# D1H register map
Vendor: Allwinner; File version: 1.0
Registers are 32-bit, read-write, reset 0x0 unless marked. A register's access mark holds for its fields unless they carry their own. Offsets are from the block's base; [hi:lo] are bit positions; {n}, {i} and the like mark numbered series; 'fields as' and 'values as' point back to an identical list.

## TWI[{n}] — Two Wire Interface
Base 0x02502000; array of 4, step 0x400
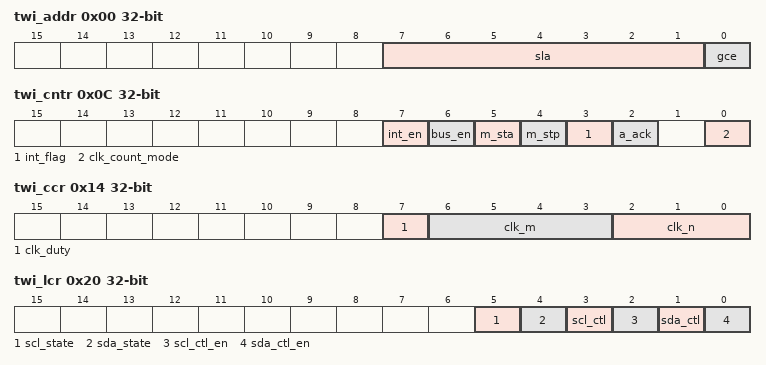
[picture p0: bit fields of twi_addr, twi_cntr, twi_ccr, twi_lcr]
0x00 twi_addr — TWI Slave Address Register
  [7:1] sla — Slave Address
  [0] gce
    0=DISABLE; 1=ENABLE
0x04 twi_xaddr — TWI Extended Slave Address Register
  [7:0] slax — Extend Slave Address . SLAX[7:0]
0x08 twi_data — TWI Data Byte Register
  [7:0] data — Data byte transmitted or received
0x0C twi_cntr — TWI Control Register
  [7] int_en — Interrupt Enable
    0=LOW (The interrupt line always low); 1=HIGH (The interrupt line will go high when INT_FLAG is set)
  [6] bus_en — TWI Bus Enable
    0=IGNORED; 1=RESPOND
  [5] m_sta — Master Mode Start
  [4] m_stp — Master Mode Stop
  [3] int_flag — Interrupt Flag
  [2] a_ack — Assert Acknowledge
  [0] clk_count_mode
    0=OSCL (scl clock high period count on oscl); 1=ISCL (scl clock high period count on iscl)
0x10 twi_stat ro — TWI Status Register
  [7:0] sta
    0=BE (Bus error); 8=SCT (START condition transmitted); 16=RSCT (Repeated START condition transmitted); 24=AWBT_AR (Address + Write bit transmitted, ACK received); 32=AWBT_ANR (Address + Write bit transmitted, ACK not received); 40=DBTM_AR (Data byte transmitted in master mode, ACK received); 48=DBTM_ANR (Data byte transmitted in master mode, ACK not received); 56=AL_A_DB (Arbitration lost in address or data byte); 64=ARBT_AR (Address + Read bit transmitted, ACK received); 72=ARBT_ANR (Address + Read bit transmitted, ACK not received); 80=DBRM_AT (Data byte received in master mode, ACK transmitted); 88=DBRM_ANT (Data byte received in master mode, not ACK transmitted); 96=SAWR_AT (Slave address + Write bit received, ACK transmitted); 104=AL_AM_SAWR_AT (Arbitration lost in the address as master, slave address + Write bit received, ACK transmitted); 112=GCAR_AT (General Call address received, ACK transmitted); 120=AL_AM_GCAR_AT (Arbitration lost in the address as master, General Call address received, ACK transmitted); 128=DBR_SAR_AT (Data byte received after slave address received, ACK transmitted); 136=DBR_SAR_ANT (Data byte received after slave address received, not ACK transmitted); 144=DBR_GCR_AT (Data byte received after General Call received, ACK transmitted); 152=DBR_GCR_ANT (Data byte received after General Call received, not ACK transmitted); 160=SRSCRS (STOP or repeated START condition received in slave mode); 168=SARR_AT (Slave address + Read bit received, ACK transmitted); 176=AL_AM_SARR_AT (Arbitration lost in the address as master, slave address + Read bit received, ACK transmitted); 184=DBTS_AR (Data byte transmitted in slave mode, ACK received); 192=DBTS_ANR (Data byte transmitted in slave mode, ACK not received); 200=LBTS_AR (The Last byte transmitted in slave mode, ACK received); 208=SAWT_AR (Second Address byte + Write bit transmitted, ACK received); 216=SAWT_ANR (Second Address byte + Write bit transmitted, ACK not received); 248=NRSI (No relevant status information, INT_FLAG=0)
0x14 twi_ccr — TWI Clock Control Register
  [7] clk_duty — Setting duty cycle of clock as master
    0=P50 (50%); 1=P40 (40%)
  [6:3] clk_m
  [2:0] clk_n
0x18 twi_srst — TWI Software Reset Register
  [0] soft_rst — Soft Reset
0x1C twi_efr — TWI Enhance Feature Register
  [1:0] dbn — Data Byte Number Follow Read Command Control
    0=B0 (No data byte can be written after the read command); 1=B1 (1-byte data can be written after the read command); 2=B2 (2-byte data can be written after the read command); 3=B3 (3-byte data can be written after the read command)
0x20 twi_lcr — TWI Line Control Register
  [5] scl_state ro — Current State of TWI_SCL
    0=LOW; 1=HIGH
  [4] sda_state ro — Current State of TWI_SDA
    0=LOW; 1=HIGH
  [3] scl_ctl — TWI_SCL Line State Control Bit
    0=LOW; 1=HIGH
  [2] scl_ctl_en — TWI_SCL Line State Control Enable
    0=DISABLE; 1=ENABLE
  [1] sda_ctl — TWI_SDA Line State Control Bit
    0=LOW; 1=HIGH
  [0] sda_ctl_en — TWI_SDA Line State Control Enable
    0=DISABLE; 1=ENABLE
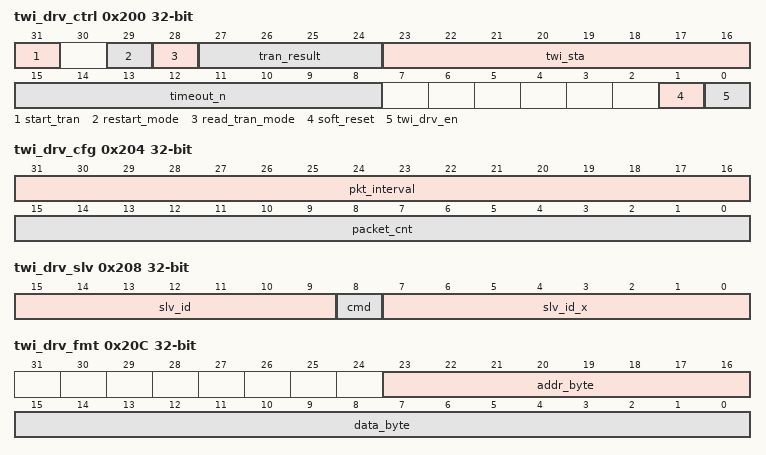
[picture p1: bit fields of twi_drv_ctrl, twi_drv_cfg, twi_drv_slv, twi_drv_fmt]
0x200 twi_drv_ctrl — TWI_DRV Control Register
  [31] start_tran — Start transmission
    0=IDLE; 1=START
  [29] restart_mode
    0=RESTART; 1=STOP_RESTART
  [28] read_tran_mode — Read transition mode
    0=SEND; 1=NOT_SEND
  [27:24] tran_result — Transition result
    0=OK; 1=FAIL
  [23:16] twi_sta ro — TWI status
    0=BE (bus error); 8=SCT (START condition transmitted); 16=RSCT (Repeated START condition transmitted); 24=AWBT_AR (Address + Write bit transmitted, ACK received); 32=AWBT_ANR (Address + Write bit transmitted, ACK not received); 40=DBTM_AR (Data byte transmitted in master mode, ACK received); 48=DBTM_ANR (Data byte transmitted in master mode, ACK not received); 56=AL_A_DB (Arbitration lost in address or data byte); 64=ARBT_AR (Address + Read bit transmitted, ACK received); 72=ARBT_ANR (Address + Read bit transmitted, ACK not received); 80=DBRM_AR (Data byte received in master mode, ACK received); 88=DBRM_ANR (Data byte received in master mode, ACK not received); 1=T_S9SC (Timeout when sending the 9th SCL clock)
  [15:8] timeout_n — Timeout number
  [1] soft_reset — Software reset
    0=NORMAL; 1=RESET
  [0] twi_drv_en
    0=DISABLE; 1=ENABLE
0x204 twi_drv_cfg — TWI_DRV Transmission Configuration Register
  [31:16] pkt_interval, [15:0] packet_cnt
0x208 twi_drv_slv — TWI_DRV Slave ID Register
  [15:9] slv_id — Slave device ID
  [8] cmd — R/W operation to slave device
    0=WRITE; 1=READ
  [7:0] slv_id_x — SLAX[7:0]
0x20C twi_drv_fmt — TWI_DRV Packet Format Register
  [23:16] addr_byte, [15:0] data_byte
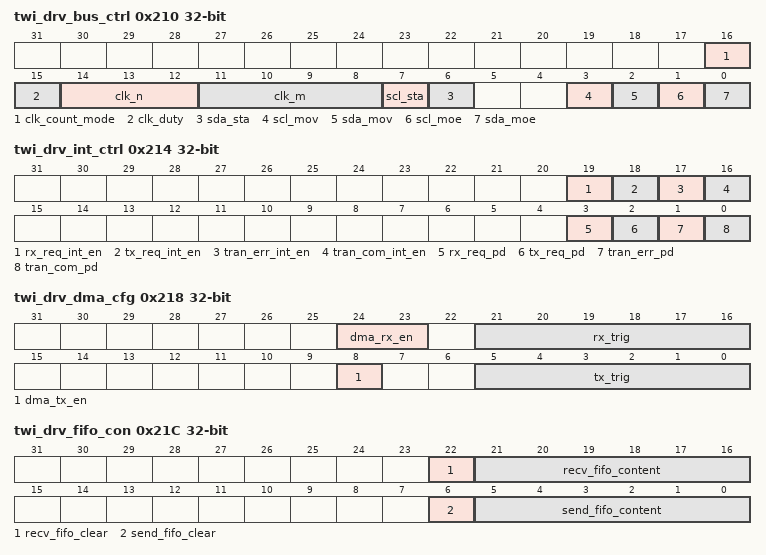
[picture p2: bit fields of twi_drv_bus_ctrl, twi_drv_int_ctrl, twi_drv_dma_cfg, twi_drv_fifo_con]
0x210 twi_drv_bus_ctrl — TWI_DRV Bus Control Register
  [16] clk_count_mode wo
    values as twi_cntr.clk_count_mode
  [15] clk_duty — Setting duty cycle of clock as master
    0=P50 (50%); 1=P40 (40%)
  [14:12] clk_n
  [11:8] clk_m
  [7] scl_sta ro — SCL current status
  [6] sda_sta ro — SDA current status
  [3] scl_mov — SCL manual output value
  [2] sda_mov — SDA manual output value
  [1] scl_moe — SCL manual output enable
  [0] sda_moe — SDA manual output enable
0x214 twi_drv_int_ctrl — TWI_DRV Interrupt Control Register
  [19] rx_req_int_en, [18] tx_req_int_en, [17] tran_err_int_en, [16] tran_com_int_en, [3] rx_req_pd, [2] tx_req_pd, [1] tran_err_pd, [0] tran_com_pd
0x218 twi_drv_dma_cfg — TWI_DRV DMA Configure Register
  [24:23] dma_rx_en, [21:16] rx_trig, [8] dma_tx_en, [5:0] tx_trig
0x21C twi_drv_fifo_con — TWI_DRV FIFO Content Register
  [22] recv_fifo_clear, [21:16] recv_fifo_content, [6] send_fifo_clear, [5:0] send_fifo_content
0x300 twi_drv_send_fifo_acc wo — TWI_DRV Send Data FIFO Access Register
  [7:0] send_data_fifo
0x304 twi_drv_recv_fifo_acc ro — TWI_DRV Receive Data FIFO Access Register
  [7:0] recv_data_fifo
